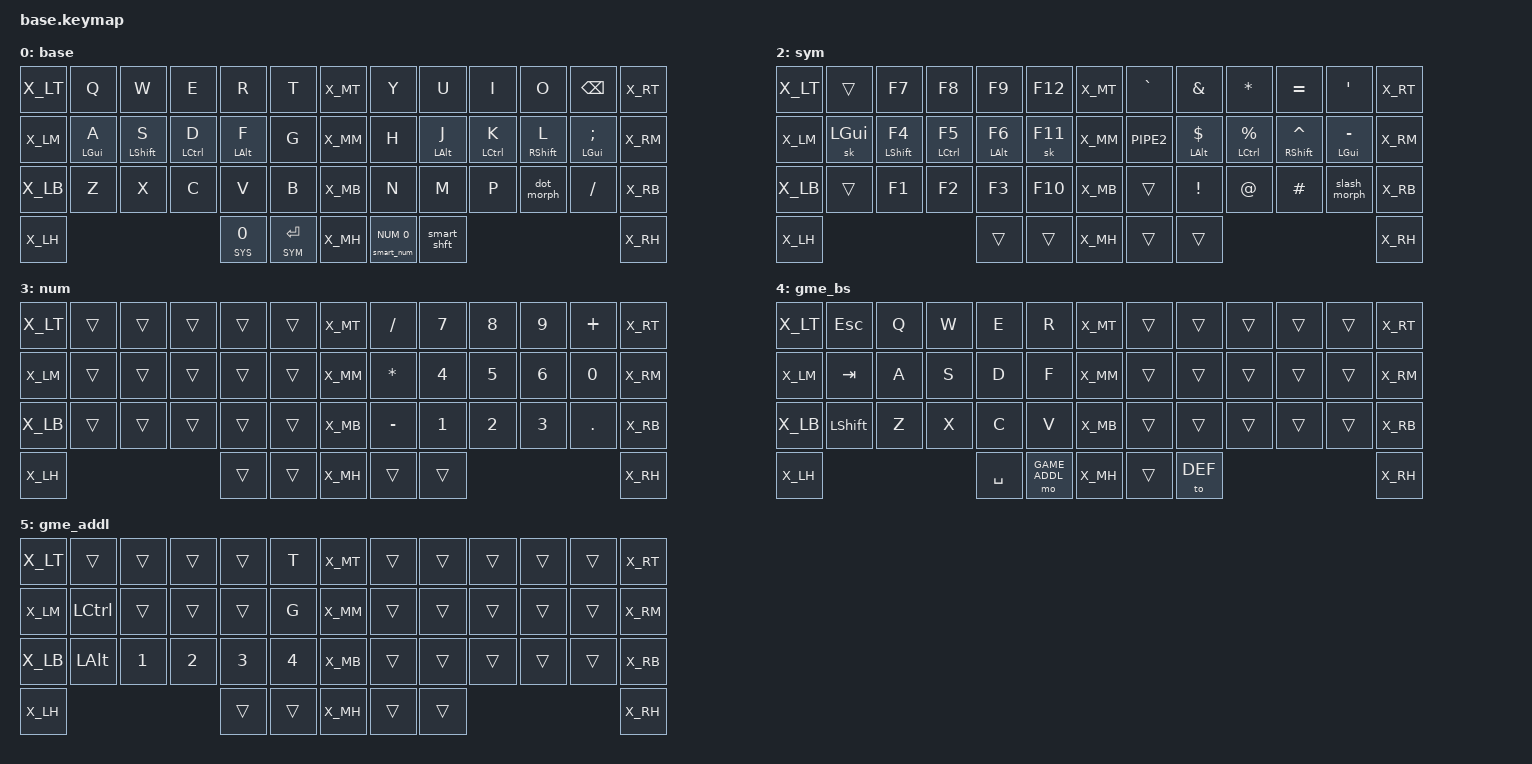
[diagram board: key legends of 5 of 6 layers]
#include <behaviors.dtsi>
#include <dt-bindings/zmk/keys.h>
#if CONFIG_WIRELESS
    #include <dt-bindings/zmk/bt.h>
    #define _BT_SEL_KEYS_ &bt BT_SEL 0 &bt BT_SEL 1 &bt BT_SEL 2 &bt BT_CLR
#else
    #define _BT_SEL_KEYS_ &trans &trans &trans &trans
#endif

#include "../zmk-nodefree-config/helper.h"
#include "../zmk-nodefree-config/international_chars/greek.dtsi"
#include "../zmk-nodefree-config/international_chars/german.dtsi"

// #define DEF 0
// #define NAV 1
// #define FN 2
// #define NUM 3
// #define SYS 4
// #define UC 5
// #define MOUSE 6


#define DEF 0
#define SYS 1
#define SYM 2
#define NUM 3
#define GAME_BASE 4
#define GAME_ADDL 5

#include "combos.dtsi"  // requires layer aliases
#include "mouse.dtsi"
#include "extra_keys.h"

#define XXX &none
#define ___ &trans

/* Global settings */

#define QUICK_TAP_MS 175

&sk {  // sticky-key config
    release-after-ms = <900>;  // release after 0.6s
    quick-release;             // no double capitalization when rolling keys
};

&sl {  // sticky-layer config
    ignore-modifiers;          // allow chording sticky mods & layers
};

&lt {  // layer-tap config
    flavor = "balanced";
    tapping-term-ms = <200>;
    quick-tap-ms = <QUICK_TAP_MS>;
};

/* Homerow mods */

#define KEYS_L LT0 LT1 LT2 LT3 LT4 LM0 LM1 LM2 LM3 LM4 LB0 LB1 LB2 LB3 LB4  // left hand
#define KEYS_R RT0 RT1 RT2 RT3 RT4 RM0 RM1 RM2 RM3 RM4 RB0 RB1 RB2 RB3 RB4  // right hand
#define THUMBS LH1 LH0 RH0 RH1                                      // thumbs

#define MAKE_HRM(NAME, HOLD, TAP, TRIGGER_POS) \
    ZMK_BEHAVIOR(NAME, hold_tap, \
        flavor = "balanced"; \
        tapping-term-ms = <280>; \
        quick-tap-ms = <QUICK_TAP_MS>; \
        require-prior-idle-ms = <150>; \
        bindings = <HOLD>, <TAP>; \
        hold-trigger-key-positions = <TRIGGER_POS>; \
        hold-trigger-on-release; \
    )
MAKE_HRM(hml, &kp, &kp, KEYS_R THUMBS)  // left-hand HRMs
MAKE_HRM(hmr, &kp, &kp, KEYS_L THUMBS)  // right-hand HRMs

MAKE_HRM(hml_repeat, &kp, &key_repeat, KEYS_R THUMBS)  // used for HRM-combo
MAKE_HRM(hmr_lpar_lt, &kp, &lpar_lt, KEYS_L THUMBS)    // "    "   "   "
MAKE_HRM(hmr_rpar_gt, &kp, &rpar_gt, KEYS_L THUMBS)    // "    "   "   "

/* Nav cluster */

// long-tap action on hold, short-tap action on all interrupts
#define MT_CORE \
    flavor = "tap-preferred"; \
    tapping-term-ms = <220>; \
    quick-tap-ms = <220>; \
    hold-trigger-key-positions = <0>;

&mt { MT_CORE };
ZMK_BEHAVIOR(mt_home, hold_tap, bindings = <&masked_home>, <&kp>; MT_CORE)
ZMK_BEHAVIOR(mt_end,  hold_tap,  bindings = <&masked_end>, <&kp>; MT_CORE)

#define NAV_LEFT  &mt_home 0   LEFT    // tap: left  | long-tap: beginning of line
#define NAV_RIGHT &mt_end 0    RIGHT   // tap: right | long-tap: end       of line
#define NAV_UP    &mt LC(HOME) UP      // tap: up    | long-tap: beginning of document
#define NAV_DOWN  &mt LC(END)  DOWN    // tap: down  | long-tap: end       of document
#define NAV_BSPC  &mt LC(BSPC) BSPC    // tap: bspc  | long-tap: delete word backward
#define NAV_DEL   &mt LC(DEL)  DEL     // tap: del   | long-tap: delete word forward

// mask CTRL when holding left/right to avoid accidental jumps to beginning/end of document
#define MASK_MODS(NAME, MODS, BINDING) \
    ZMK_BEHAVIOR(NAME, mod_morph, \
        bindings = <BINDING>, <BINDING>; \
        mods = <MODS>; \
    )
MASK_MODS(masked_home, (MOD_LCTL), &kp HOME)
MASK_MODS(masked_end,  (MOD_LCTL), &kp END)

/* Caps-word, num-word and smart-mouse */

// tap: sticky-shift | shift + tap/ double-tap: caps-word | hold: shift
ZMK_BEHAVIOR(smart_shft, mod_morph,
    bindings = <&sk LSHFT>, <&caps_word>;
    mods = <(MOD_LSFT)>;
)
&caps_word {  // mods deactivate caps-word, requires PR #1451
    /delete-property/ ignore-modifiers;
};

// tap: num-word | double-tap: sticky num-layer | hold: num-layer
#define SMART_NUM &smart_num NUM 0
ZMK_BEHAVIOR(smart_num, hold_tap,
    flavor = "balanced";
    tapping-term-ms = <200>;
    quick-tap-ms = <QUICK_TAP_MS>;
    bindings = <&mo>, <&num_dance>;
)
ZMK_BEHAVIOR(num_dance, tap_dance,
    tapping-term-ms = <200>;
    bindings = <&num_word>, <&sl NUM>;  // reverse this for sticky-num on single tap
)
&num_word {  // num-word, requires PR #1451
    layers = <NUM>;
    continue-list = <BSPC DEL DOT COMMA PLUS MINUS STAR FSLH EQUAL>;
};

/* Custom behaviors */

// Alt+Tab swapper, requires PR #1366
ZMK_BEHAVIOR(swapper, tri_state,
    bindings = <&kt LALT>, <&kp TAB>, <&kt LALT>;
    ignored-key-positions = <LT2>;
)

// reuse basic mod-morph scheme
#define SIMPLE_MORPH(NAME, MOD, BINDING1, BINDING2) \
    ZMK_BEHAVIOR(NAME, mod_morph, \
        mods = <(MOD_L ## MOD|MOD_R ## MOD)>; \
        bindings = <BINDING1>, <BINDING2>; \
    )

// tap: comma | shift + tap: semicolon | ctrl + shift + tap: <
SIMPLE_MORPH(comma_morph, SFT, &kp COMMA, &comma_inner_morph)
SIMPLE_MORPH(comma_inner_morph, CTL, &kp SEMICOLON, &kp LESS_THAN)

// tap: dot | shift + tap: colon | ctrl + shift + tap: >
SIMPLE_MORPH(dot_morph, SFT, &kp DOT, &kp COMMA)
SIMPLE_MORPH(dot_inner_morph, CTL, &kp COLON, &kp GREATER_THAN)

// tap: qmark | shift + tap: excl
SIMPLE_MORPH(qexcl, SFT, &kp QMARK, &kp EXCL)

// tap: left/right parenthesis | shft + tap: less-than/greater-than
SIMPLE_MORPH(lpar_lt, SFT, &kp LPAR, &kp LT)
SIMPLE_MORPH(rpar_gt, SFT, &kp RPAR, &kp GT)

SIMPLE_MORPH(slash_morph, SFT, &kp FSLH, &kp BACKSLASH)
SIMPLE_MORPH(lpar_rpar, SFT, &kp LPAR, &kp RPAR)
SIMPLE_MORPH(lt_gt, SFT, &kp LT, &kp GT)
SIMPLE_MORPH(lbrack_rbrack, SFT, &kp LEFT_BRACKET, &kp RIGHT_BRACKET)
SIMPLE_MORPH(lcurl_rcurl, SFT, &kp LEFT_BRACE, &kp RIGHT_BRACE)

// tap: space | shift + tap: dot -> space -> sticky shift | hold: activate layer
ZMK_BEHAVIOR(lt_spc, hold_tap,
    flavor = "balanced";
    tapping-term-ms = <200>;
    quick-tap-ms = <QUICK_TAP_MS>;
    bindings = <&mo>, <&spc_morph>;
)
SIMPLE_MORPH(spc_morph, SFT, &kp SPACE, &dot_spc)
ZMK_BEHAVIOR(dot_spc, macro,
    wait-ms = <0>;
    tap-ms = <5>;
    bindings = <&kp DOT &kp SPACE &sk LSHFT>;
)

// tap: backspace | lshft + tap: delete | rshft + tap: shift-delete
ZMK_BEHAVIOR(bs_del, mod_morph,
    bindings = <&kp BSPC>, <&kp DEL>;
    mods = <(MOD_LSFT|MOD_RSFT)>;
    keep-mods = <MOD_RSFT>;
)

// tap: copy | double-tap: cut
ZMK_BEHAVIOR(copy_cut, tap_dance,
    tapping-term-ms = <200>;
    bindings = <&kp LC(INS)>, <&kp LC(X)>;
)

// Windows sleep key
ZMK_BEHAVIOR(win_sleep, macro,
    wait-ms = <500>;
    tap-ms = <50>;
    bindings = <&kp LG(X) &kp U &kp S>;
)

// misc aliases
#define CANCEL      &kp K_CANCEL             // cancel caps-word, num-word and smart-mouse
#define TO_BASE     &to DEF
#define DSK_PREV    &hmr RSHFT LG(LC(LEFT))  // previous desktop
#define DSK_NEXT    &hmr LALT LG(LC(RIGHT))  // next     desktop
#define PIN_WIN     &kp LG(LC(LS(Q)))        // pin window across desktops
#define PIN_APP     &kp LG(LC(LS(A)))        // pin application across desktops
#define DSK_MGR     &kp LA(GRAVE)            // desktop manager
#define VOL_DOWN    &hmr LCTRL C_VOL_DN

#define NXT_TAB     LC(TAB)
#define PRV_TAB     LC(LS(TAB))
#define NXT_WIN     LA(TAB)

/* Keymap */

// ZMK_CONDITIONAL_LAYER(FN NUM, SYS)  // FN + NUM --> SYS

ZMK_LAYER(base,
//╭──────╮ ╭─────────────┬─────────────┬─────────────┬─────────────┬─────────────╮ ╭──────╮ ╭─────────────┬─────────────┬─────────────┬─────────────┬─────────────╮ ╭──────╮
    X_LT     &kp Q         &kp W         &kp E         &kp R         &kp T           X_MT     &kp Y         &kp U         &kp I         &kp O         &kp BACKSPACE   X_RT
//├──────┤ ├─────────────┼─────────────┼─────────────┼─────────────┼─────────────┤ ├──────┤ ├─────────────┼─────────────┼─────────────┼─────────────┼─────────────┤ ├──────┤
    X_LM     &hml LGUI A   &hml LSHIFT S &hml LCTRL D  &hml LALT F   &kp G           X_MM     &kp H         &hmr LALT J   &hmr LCTRL K  &hmr RSHIFT L &hmr LGUI SEMI  X_RM
//├──────┤ ├─────────────┼─────────────┼─────────────┼─────────────┼─────────────┤ ├──────┤ ├─────────────┼─────────────┼─────────────┼─────────────┼─────────────┤ ├──────┤
    X_LB     &kp Z         &kp X         &kp C         &kp V         &kp B           X_MB     &kp N         &kp M         &kp P         &dot_morph    &kp FSLH        X_RB
//├──────┤ ╰─────────────┼─────────────┴─────────────┼─────────────┼─────────────┤ ├──────┤ ├─────────────┼─────────────┼─────────────┴───────────────────────────╯ ├──────┤
    X_LH                                               &lt_spc SYS 0 &lt SYM RET     X_MH     SMART_NUM     &smart_shft                                               X_RH
//╰──────╯                                           ╰─────────────┴─────────────╯ ╰──────╯ ╰─────────────┴─────────────╯                                           ╰──────╯
)

ZMK_LAYER(sys,
//╭──────╮ ╭─────────────┬─────────────┬─────────────┬─────────────┬─────────────╮ ╭──────╮ ╭─────────────┬─────────────┬─────────────┬─────────────┬─────────────╮ ╭──────╮
    X_LT     &bootloader   _BT_SEL_KEYS_                                             X_MT     &kp PG_UP     &kp C_VOL_DN  &kp UP        &kp C_VOL_UP  &bootloader     X_RT
//├──────┤ ├─────────────┼─────────────┼─────────────┼─────────────┼─────────────┤ ├──────┤ ├─────────────┼─────────────┼─────────────┼─────────────┼─────────────┤ ├──────┤
    X_LM     &hml LGUI TAB
                          &hml LSHIFT NXT_TAB
                                         &hml LCTRL NXT_WIN
                                                       &hml LALT ESC
                                                                     ___             X_MM     &kp PG_DN     &hmr LALT LEFT
                                                                                                                          &hmr LCTRL DOWN 
                                                                                                                                        &hmr RSHIFT RIGHT
                                                                                                                                                     &hmr LGUI DEL    X_RM
//├──────┤ ├─────────────┼─────────────┼─────────────┼─────────────┼─────────────┤ ├──────┤ ├─────────────┼─────────────┼─────────────┼─────────────┼─────────────┤ ├──────┤
    X_LB     &sys_reset    &kp PRV_TAB   ___           ___           &to GAME_BASE   X_MB     &kp INS       &kp C_PP      &kp C_PREV    &kp C_NEXT    &sys_reset      X_RB
//├──────┤ ╰─────────────┼─────────────┴─────────────┼─────────────┼─────────────┤ ├──────┤ ├─────────────┼─────────────┼─────────────┴───────────────────────────╯ ├──────┤
    X_LH                                               ___           ___             X_MH     ___           CANCEL                                                    X_RH
//╰──────╯                                           ╰─────────────┴─────────────╯ ╰──────╯ ╰─────────────┴─────────────╯                                           ╰──────╯
)

ZMK_LAYER(sym,
//╭──────╮ ╭─────────────┬─────────────┬─────────────┬─────────────┬─────────────╮ ╭──────╮ ╭─────────────┬─────────────┬─────────────┬─────────────┬─────────────╮ ╭──────╮
    X_LT    ___           &kp F7        &kp F8        &kp F9        &kp F12          X_MT     &kp GRAVE     &kp AMPS      &kp STAR      &kp EQUAL     &kp SINGLE_QUOTE X_RT
//├──────┤ ├─────────────┼─────────────┼─────────────┼─────────────┼─────────────┤ ├──────┤ ├─────────────┼─────────────┼─────────────┼─────────────┼─────────────┤ ├──────┤
    X_LM    &sk LGUI      &hml LSHIFT F4 &hml LCTRL F5 &hml LALT F6 &sk F11          X_MM     &kp PIPE2    &hmr LALT DOLLAR
                                                                                                                         &hmr LCTRL PERCENT 
                                                                                                                                       &hmr RSHIFT CARET
                                                                                                                                                     &hmr LGUI MINUS  X_RM
//├──────┤ ├─────────────┼─────────────┼─────────────┼─────────────┼─────────────┤ ├──────┤ ├─────────────┼─────────────┼─────────────┼─────────────┼─────────────┤ ├──────┤
    X_LB    ___           &kp F1        &kp F2        &kp F3        &kp F10          X_MB     ___           &kp EXCL      &kp AT_SIGN   &kp HASH      &slash_morph    X_RB
//├──────┤ ╰─────────────┼─────────────┴─────────────┼─────────────┼─────────────┤ ├──────┤ ├─────────────┼─────────────┼─────────────┴───────────────────────────╯ ├──────┤
    X_LH                                               ___           ___             X_MH     ___           ___                                                       X_RH
//╰──────╯                                           ╰─────────────┴─────────────╯ ╰──────╯ ╰─────────────┴─────────────╯                                           ╰──────╯
)

ZMK_LAYER(num,
//╭──────╮ ╭─────────────┬─────────────┬─────────────┬─────────────┬─────────────╮ ╭──────╮ ╭─────────────┬─────────────┬─────────────┬─────────────┬─────────────╮ ╭──────╮
    X_LT     ___           ___           ___           ___           ___             X_MT     &kp FSLH      &kp N7        &kp N8        &kp N9        &kp PLUS        X_RT
//├──────┤ ├─────────────┼─────────────┼─────────────┼─────────────┼─────────────┤ ├──────┤ ├─────────────┼─────────────┼─────────────┼─────────────┼─────────────┤ ├──────┤
    X_LM     ___           ___           ___           ___           ___             X_MM     &kp STAR      &kp N4        &kp N5        &kp N6        &kp N0          X_RM
//├──────┤ ├─────────────┼─────────────┼─────────────┼─────────────┼─────────────┤ ├──────┤ ├─────────────┼─────────────┼─────────────┼─────────────┼─────────────┤ ├──────┤
    X_LB     ___           ___           ___           ___           ___             X_MB     &kp MINUS     &kp N1        &kp N2        &kp N3        &kp DOT         X_RB
//├──────┤ ╰─────────────┼─────────────┴─────────────┼─────────────┼─────────────┤ ├──────┤ ├─────────────┼─────────────┼─────────────┴───────────────────────────╯ ├──────┤
    X_LH                                               ___           ___             X_MH     ___           ___                                                       X_RH
//╰──────╯                                           ╰─────────────┴─────────────╯ ╰──────╯ ╰─────────────┴─────────────╯                                           ╰──────╯
)


ZMK_LAYER(gme_bs,
//╭──────╮ ╭─────────────┬─────────────┬─────────────┬─────────────┬─────────────╮ ╭──────╮ ╭─────────────┬─────────────┬─────────────┬─────────────┬─────────────╮ ╭──────╮
    X_LT     &kp ESC       &kp Q         &kp W         &kp E         &kp R           X_MT     ___           ___           ___           ___           ___             X_RT
//├──────┤ ├─────────────┼─────────────┼─────────────┼─────────────┼─────────────┤ ├──────┤ ├─────────────┼─────────────┼─────────────┼─────────────┼─────────────┤ ├──────┤
    X_LM     &kp TAB       &kp A         &kp S         &kp D         &kp F           X_MM     ___           ___           ___           ___           ___             X_RM
//├──────┤ ├─────────────┼─────────────┼─────────────┼─────────────┼─────────────┤ ├──────┤ ├─────────────┼─────────────┼─────────────┼─────────────┼─────────────┤ ├──────┤
    X_LB     &kp LSHIFT    &kp Z         &kp X         &kp C         &kp V           X_MB     ___           ___           ___           ___           ___             X_RB
//├──────┤ ╰─────────────┼─────────────┴─────────────┼─────────────┼─────────────┤ ├──────┤ ├─────────────┼─────────────┼─────────────┴───────────────────────────╯ ├──────┤
    X_LH                                               &kp SPACE     &mo GAME_ADDL   X_MH     ___           TO_BASE                                                   X_RH
//╰──────╯                                           ╰─────────────┴─────────────╯ ╰──────╯ ╰───────────────────────────╯                                           ╰──────╯
)

ZMK_LAYER(gme_addl,
//╭──────╮ ╭─────────────┬─────────────┬─────────────┬─────────────┬─────────────╮ ╭──────╮ ╭─────────────┬─────────────┬─────────────┬─────────────┬─────────────╮ ╭──────╮
    X_LT     ___           ___           ___           ___           &kp T           X_MT     ___           ___           ___           ___           ___             X_RT
//├──────┤ ├─────────────┼─────────────┼─────────────┼─────────────┼─────────────┤ ├──────┤ ├─────────────┼─────────────┼─────────────┼─────────────┼─────────────┤ ├──────┤
    X_LM     &kp LCTRL     ___           ___           ___           &kp G           X_MM     ___           ___           ___           ___           ___             X_RM
//├──────┤ ├─────────────┼─────────────┼─────────────┼─────────────┼─────────────┤ ├──────┤ ├─────────────┼─────────────┼─────────────┼─────────────┼─────────────┤ ├──────┤
    X_LB     &kp LALT      &kp N1        &kp N2        &kp N3        &kp N4          X_MB     ___           ___           ___           ___           ___             X_RB
//├──────┤ ╰─────────────┼─────────────┴─────────────┼─────────────┼─────────────┤ ├──────┤ ├─────────────┼─────────────┼─────────────┴───────────────────────────╯ ├──────┤
    X_LH                                               ___           ___             X_MH     ___           ___                                                       X_RH
//╰──────╯                                           ╰─────────────┴─────────────╯ ╰──────╯ ╰───────────────────────────╯                                           ╰──────╯
)


/* vim: set ft=c tw=174: */
